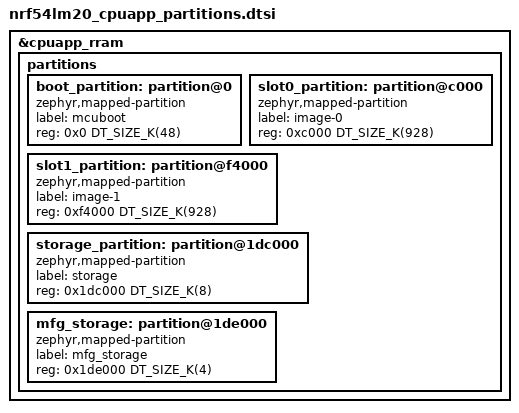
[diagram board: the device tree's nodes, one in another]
/*
 * Copyright (c) 2026 Nordic Semiconductor ASA
 *
 * SPDX-License-Identifier: LicenseRef-Nordic-5-Clause
 */

/delete-node/ &boot_partition;
/delete-node/ &slot0_partition;
/delete-node/ &slot1_partition;
/delete-node/ &storage_partition;

&cpuapp_rram {
	partitions {
		ranges;
		#address-cells = <1>;
		#size-cells = <1>;

		boot_partition: partition@0 {
			compatible = "zephyr,mapped-partition";
			label = "mcuboot";
			reg = <0x0 DT_SIZE_K(48)>;
		};

		slot0_partition: partition@c000 {
			compatible = "zephyr,mapped-partition";
			label = "image-0";
			reg = <0xc000 DT_SIZE_K(928)>;
		};

		slot1_partition: partition@f4000 {
			compatible = "zephyr,mapped-partition";
			label = "image-1";
			reg = <0xf4000 DT_SIZE_K(928)>;
		};

		storage_partition: partition@1dc000 {
			compatible = "zephyr,mapped-partition";
			label = "storage";
			reg = <0x1dc000 DT_SIZE_K(8)>;
		};

		mfg_storage: partition@1de000 {
			compatible = "zephyr,mapped-partition";
			label = "mfg_storage";
			reg = <0x1de000 DT_SIZE_K(4)>;
		};
	};
};
